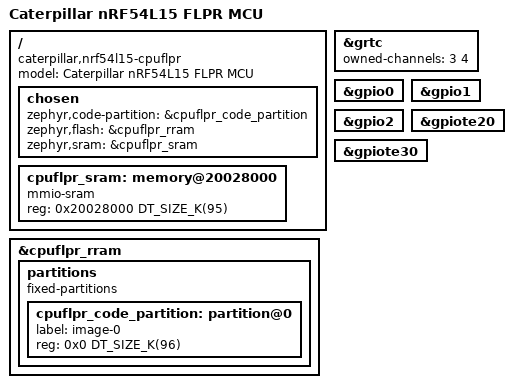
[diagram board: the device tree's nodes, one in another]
/*
 * Copyright (c) 2024 Nordic Semiconductor ASA
 *
 * SPDX-License-Identifier: Apache-2.0
 */

/dts-v1/;
#include <nordic/nrf54l15_cpuflpr.dtsi>
#include "caterpillar_common.dtsi"

/delete-node/ &cpuflpr_sram;

/ {
	model = "Caterpillar nRF54L15 FLPR MCU";
	compatible = "caterpillar,nrf54l15-cpuflpr";

	chosen {
		zephyr,code-partition = &cpuflpr_code_partition;
		zephyr,flash = &cpuflpr_rram;
		zephyr,sram = &cpuflpr_sram;
	};

	cpuflpr_sram: memory@20028000 {
		compatible = "mmio-sram";
		/* Boots from SRAM.  96 KB minus the top 1 KB, which is the
		 * IMU shared block read by the app core
		 * (common/imu_shared.h, 0x2003FC00).
		 */
		reg = <0x20028000 DT_SIZE_K(95)>;
		#address-cells = <1>;
		#size-cells = <1>;
		ranges = <0x0 0x20028000 0x17c00>;
		status = "okay";
	};
};

&cpuflpr_rram {
	partitions {
		compatible = "fixed-partitions";
		#address-cells = <1>;
		#size-cells = <1>;

		cpuflpr_code_partition: partition@0 {
			label = "image-0";
			reg = <0x0 DT_SIZE_K(96)>;
		};
	};
};

&grtc {
	owned-channels = <3 4>;
	status = "okay";
};

&gpio0 {
	status = "okay";
};

&gpio1 {
	status = "okay";
};

&gpio2 {
	status = "okay";
};

&gpiote20 {
	status = "okay";
};

&gpiote30 {
	status = "okay";
};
